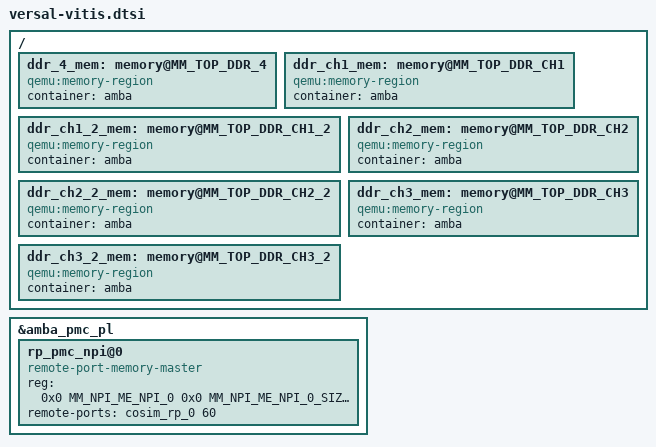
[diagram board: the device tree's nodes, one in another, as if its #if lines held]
/*
 * Versal Vitis specific nodes
 *
 * Copyright (c) 2021, Xilinx Inc
 * All rights reserved.
 *
 * Redistribution and use in source and binary forms, with or without
 * modification, are permitted provided that the following conditions are met:
 *     * Redistributions of source code must retain the above copyright
 *       notice, this list of conditions and the following disclaimer.
 *     * Redistributions in binary form must reproduce the above copyright
 *       notice, this list of conditions and the following disclaimer in the
 *       documentation and/or other materials provided with the distribution.
 *     * Neither the name of the <organization> nor the
 *       names of its contributors may be used to endorse or promote products
 *       derived from this software without specific prior written permission.
 *
 * THIS SOFTWARE IS PROVIDED BY THE COPYRIGHT HOLDERS AND CONTRIBUTORS "AS IS" AND
 * ANY EXPRESS OR IMPLIED WARRANTIES, INCLUDING, BUT NOT LIMITED TO, THE IMPLIED
 * WARRANTIES OF MERCHANTABILITY AND FITNESS FOR A PARTICULAR PURPOSE ARE
 * DISCLAIMED. IN NO EVENT SHALL <COPYRIGHT HOLDER> BE LIABLE FOR ANY
 * DIRECT, INDIRECT, INCIDENTAL, SPECIAL, EXEMPLARY, OR CONSEQUENTIAL DAMAGES
 * (INCLUDING, BUT NOT LIMITED TO, PROCUREMENT OF SUBSTITUTE GOODS OR SERVICES;
 * LOSS OF USE, DATA, OR PROFITS; OR BUSINESS INTERRUPTION) HOWEVER CAUSED AND
 * ON ANY THEORY OF LIABILITY, WHETHER IN CONTRACT, STRICT LIABILITY, OR TORT
 * (INCLUDING NEGLIGENCE OR OTHERWISE) ARISING IN ANY WAY OUT OF THE USE OF THIS
 * SOFTWARE, EVEN IF ADVISED OF THE POSSIBILITY OF SUCH DAMAGE.
 */

#undef MEM_SPEC
#define MEM_SPEC	MEM_REGION64

/ {
	/delete-node/ ddr_2@MM_TOP_DDR_2;
	/delete-node/ ddr_3@MM_TOP_DDR_CH1;
	ddr_4_mem: memory@MM_TOP_DDR_4 {
		compatible = "qemu:memory-region";
		device_type = "memory";
		container = <&amba>;
	};

	ddr_ch1_mem: memory@MM_TOP_DDR_CH1 {
		compatible = "qemu:memory-region";
		device_type = "memory";
		container = <&amba>;
	};
	ddr_ch1_2_mem: memory@MM_TOP_DDR_CH1_2 {
		compatible = "qemu:memory-region";
		device_type = "memory";
		container = <&amba>;
	};

	ddr_ch2_mem: memory@MM_TOP_DDR_CH2 {
		compatible = "qemu:memory-region";
		device_type = "memory";
		container = <&amba>;
	};

	ddr_ch2_2_mem: memory@MM_TOP_DDR_CH2_2 {
		compatible = "qemu:memory-region";
		device_type = "memory";
		container = <&amba>;
	};

	ddr_ch3_mem: memory@MM_TOP_DDR_CH3 {
		compatible = "qemu:memory-region";
		device_type = "memory";
		container = <&amba>;
	};

	ddr_ch3_2_mem: memory@MM_TOP_DDR_CH3_2 {
		compatible = "qemu:memory-region";
		device_type = "memory";
		container = <&amba>;
	};
};

#if defined(MM_NPI_ME_NPI_0) || defined(MM_NPI_AIE2_NPI_0)
&amba_pmc_pl {
	rp_pmc_npi@0 {
		compatible = "remote-port-memory-master";
		reg = <
#if defined(MM_NPI_ME_NPI_0)
			0x0 MM_NPI_ME_NPI_0 0x0 MM_NPI_ME_NPI_0_SIZE 0x2
#elif defined(MM_NPI_AIE2_NPI_0)
			0x0 MM_NPI_AIE2_NPI_0 0x0 MM_NPI_AIE2_NPI_0_SIZE 0x2
#endif
			>;
		remote-ports = <&cosim_rp_0 60>;
	};
};
#endif

#ifdef __has_include
# if __has_include("ddr_memspec.dtsi")
#  include "ddr_memspec.dtsi"
# endif
#else
# warning Please include ddr_memspec.dtsi manually.
#endif
